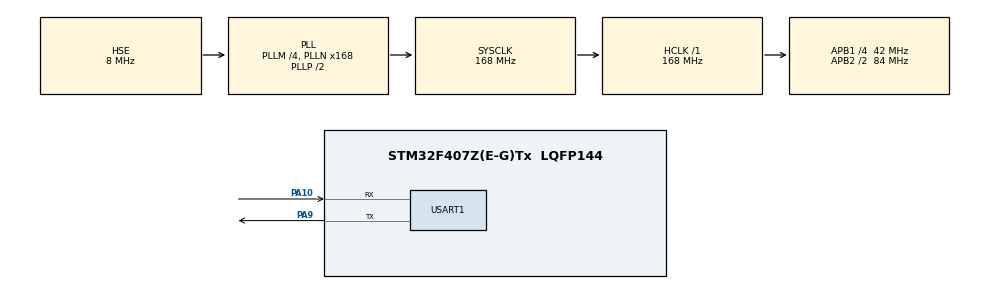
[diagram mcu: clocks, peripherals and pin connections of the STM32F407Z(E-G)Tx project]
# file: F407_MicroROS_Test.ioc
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Dma.Request0=USART1_RX
Dma.Request1=USART1_TX
Dma.USART1_RX.0.Direction=DMA_PERIPH_TO_MEMORY
Dma.USART1_RX.0.FIFOMode=DMA_FIFOMODE_DISABLE
Dma.USART1_RX.0.Instance=DMA2_Stream2
Dma.USART1_RX.0.MemDataAlignment=DMA_MDATAALIGN_BYTE
Dma.USART1_RX.0.MemInc=DMA_MINC_ENABLE
Dma.USART1_RX.0.Mode=DMA_CIRCULAR
Dma.USART1_RX.0.PeriphDataAlignment=DMA_PDATAALIGN_BYTE
Dma.USART1_RX.0.PeriphInc=DMA_PINC_DISABLE
Dma.USART1_RX.0.Priority=DMA_PRIORITY_VERY_HIGH
Dma.USART1_TX.1.Direction=DMA_MEMORY_TO_PERIPH
Dma.USART1_TX.1.FIFOMode=DMA_FIFOMODE_DISABLE
Dma.USART1_TX.1.Instance=DMA2_Stream7
Dma.USART1_TX.1.MemDataAlignment=DMA_MDATAALIGN_BYTE
Dma.USART1_TX.1.MemInc=DMA_MINC_ENABLE
Dma.USART1_TX.1.Mode=DMA_NORMAL
Dma.USART1_TX.1.PeriphDataAlignment=DMA_PDATAALIGN_BYTE
Dma.USART1_TX.1.PeriphInc=DMA_PINC_DISABLE
Dma.USART1_TX.1.Priority=DMA_PRIORITY_VERY_HIGH
FREERTOS.Tasks01=defaultTask,24,3000,StartDefaultTask,Default,NULL,Static,defaultTaskBuffer,defaultTaskControlBlock
Mcu.Family=STM32F4
Mcu.Name=STM32F407Z(E-G)Tx
Mcu.Package=LQFP144
NVIC.DMA2_Stream2_IRQn=true\:5\:0\:false\:false\:true\:true\:false\:true\:true
NVIC.DMA2_Stream7_IRQn=true\:5\:0\:false\:false\:true\:true\:false\:true\:true
NVIC.PriorityGroup=NVIC_PRIORITYGROUP_4
NVIC.TIM1_UP_TIM10_IRQn=true\:15\:0\:false\:false\:true\:false\:false\:true\:true
NVIC.TimeBase=TIM1_UP_TIM10_IRQn
NVIC.TimeBaseIP=TIM1
NVIC.USART1_IRQn=true\:5\:0\:false\:false\:true\:true\:false\:true\:true
PA10.Mode=Asynchronous
PA10.Signal=USART1_RX
PA13.Mode=Serial_Wire
PA13.Signal=SYS_JTMS-SWDIO
PA14.Mode=Serial_Wire
PA14.Signal=SYS_JTCK-SWCLK
PA9.Mode=Asynchronous
PA9.Signal=USART1_TX
PH0-OSC_IN.Mode=HSE-External-Oscillator
PH0-OSC_IN.Signal=RCC_OSC_IN
PH1-OSC_OUT.Mode=HSE-External-Oscillator
PH1-OSC_OUT.Signal=RCC_OSC_OUT
ProjectManager.HeapSize=0x200
ProjectManager.StackSize=0x400
ProjectManager.TargetToolchain=STM32CubeIDE
RCC.48MHZClocksFreq_Value=84000000
RCC.AHBFreq_Value=168000000
RCC.APB1CLKDivider=RCC_HCLK_DIV4
RCC.APB1Freq_Value=42000000
RCC.APB1TimFreq_Value=84000000
RCC.APB2CLKDivider=RCC_HCLK_DIV2
RCC.APB2Freq_Value=84000000
RCC.APB2TimFreq_Value=168000000
RCC.CortexFreq_Value=168000000
RCC.HCLKFreq_Value=168000000
RCC.HSE_VALUE=8000000
RCC.HSI_VALUE=16000000
RCC.LSE_VALUE=32768
RCC.PLLM=4
RCC.PLLN=168
RCC.PLLSourceVirtual=RCC_PLLSOURCE_HSE
RCC.SYSCLKFreq_VALUE=168000000
RCC.SYSCLKSource=RCC_SYSCLKSOURCE_PLLCLK
RCC.VCOOutputFreq_Value=336000000
USART1.VirtualMode=VM_ASYNC
VP_FREERTOS_VS_CMSIS_V2.Mode=CMSIS_V2
VP_SYS_VS_tim1.Mode=TIM1
board=custom

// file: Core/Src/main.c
/* USER CODE BEGIN Header */
/**
  ******************************************************************************
  * @file           : main.c
  * @brief          : Main program body
  ******************************************************************************
  * @attention
  *
  * Copyright (c) 2026 STMicroelectronics.
  * All rights reserved.
  *
  * This software is licensed under terms that can be found in the LICENSE file
  * in the root directory of this software component.
  * If no LICENSE file comes with this software, it is provided AS-IS.
  *
  ******************************************************************************
  */
/* USER CODE END Header */
#include "main.h"
#include "cmsis_os.h"
#include "dma.h"
#include "usart.h"
#include "gpio.h"

void SystemClock_Config(void);
void MX_FREERTOS_Init(void);

int main(void)
{

  /* MCU Configuration--------------------------------------------------------*/

  /* Reset of all peripherals, Initializes the Flash interface and the Systick. */
  HAL_Init();

  /* Configure the system clock */
  SystemClock_Config();

  /* Initialize all configured peripherals */
  MX_GPIO_Init();
  MX_DMA_Init();
  MX_USART1_UART_Init();

  /* Init scheduler */
  osKernelInitialize();  /* Call init function for freertos objects (in cmsis_os2.c) */
  MX_FREERTOS_Init();

  /* Start scheduler */
  osKernelStart();

  /* We should never get here as control is now taken by the scheduler */

  /* Infinite loop */
  while (1)
  {

  }
}

void SystemClock_Config(void)
{
  RCC_OscInitTypeDef RCC_OscInitStruct = {0};
  RCC_ClkInitTypeDef RCC_ClkInitStruct = {0};

  /** Configure the main internal regulator output voltage
  */
  __HAL_RCC_PWR_CLK_ENABLE();
  __HAL_PWR_VOLTAGESCALING_CONFIG(PWR_REGULATOR_VOLTAGE_SCALE1);

  /** Initializes the RCC Oscillators according to the specified parameters
  * in the RCC_OscInitTypeDef structure.
  */
  RCC_OscInitStruct.OscillatorType = RCC_OSCILLATORTYPE_HSE;
  RCC_OscInitStruct.HSEState = RCC_HSE_ON;
  RCC_OscInitStruct.PLL.PLLState = RCC_PLL_ON;
  RCC_OscInitStruct.PLL.PLLSource = RCC_PLLSOURCE_HSE;
  RCC_OscInitStruct.PLL.PLLM = 4;
  RCC_OscInitStruct.PLL.PLLN = 168;
  RCC_OscInitStruct.PLL.PLLP = RCC_PLLP_DIV2;
  RCC_OscInitStruct.PLL.PLLQ = 4;
  if (HAL_RCC_OscConfig(&RCC_OscInitStruct) != HAL_OK)
  {
    Error_Handler();
  }

  /** Initializes the CPU, AHB and APB buses clocks
  */
  RCC_ClkInitStruct.ClockType = RCC_CLOCKTYPE_HCLK|RCC_CLOCKTYPE_SYSCLK
                              |RCC_CLOCKTYPE_PCLK1|RCC_CLOCKTYPE_PCLK2;
  RCC_ClkInitStruct.SYSCLKSource = RCC_SYSCLKSOURCE_PLLCLK;
  RCC_ClkInitStruct.AHBCLKDivider = RCC_SYSCLK_DIV1;
  RCC_ClkInitStruct.APB1CLKDivider = RCC_HCLK_DIV4;
  RCC_ClkInitStruct.APB2CLKDivider = RCC_HCLK_DIV2;

  if (HAL_RCC_ClockConfig(&RCC_ClkInitStruct, FLASH_LATENCY_5) != HAL_OK)
  {
    Error_Handler();
  }
}

void HAL_TIM_PeriodElapsedCallback(TIM_HandleTypeDef *htim)
{
  if (htim->Instance == TIM1)
  {
    HAL_IncTick();
  }
}

void Error_Handler(void)
{
  __disable_irq();
  while (1)
  {
  }
}

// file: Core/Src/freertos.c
/* USER CODE BEGIN Header */
/**
  ******************************************************************************
  * File Name          : freertos.c
  * Description        : Code for freertos applications
  ******************************************************************************
  * @attention
  *
  * Copyright (c) 2026 STMicroelectronics.
  * All rights reserved.
  *
  * This software is licensed under terms that can be found in the LICENSE file
  * in the root directory of this software component.
  * If no LICENSE file comes with this software, it is provided AS-IS.
  *
  ******************************************************************************
  */
/* USER CODE END Header */

#include "FreeRTOS.h"
#include "task.h"
#include "main.h"
#include "cmsis_os.h"

/* USER CODE BEGIN Includes */
#include <stdbool.h>
#include <stddef.h>
#include <stdint.h>
#include <string.h>

#include <builtin_interfaces/msg/time.h>
#include <geometry_msgs/msg/transform_stamped.h>
#include <nav_msgs/msg/odometry.h>
#include <rcl/rcl.h>
#include <rcl/error_handling.h>
#include <rclc/rclc.h>
#include <rclc/executor.h>
#include <rcutils/allocator.h>
#include <rmw_microros/rmw_microros.h>
#include <rosidl_runtime_c/string_functions.h>
#include <std_msgs/msg/int32.h>
#include <tf2_msgs/msg/tf_message.h>
#include <uxr/client/transport.h>

#include "usart.h"
/* USER CODE END Includes */

typedef StaticTask_t osStaticThreadDef_t;

/* USER CODE BEGIN PD */
#define ODOM_FRAME_ID                 "odom"
#define BASE_FOOTPRINT_FRAME_ID       "base_footprint"
#define ODOM_TIMER_PERIOD_MS          50U
#define ODOM_LINEAR_X_MPS             0.1
#define PING_TIMER_PERIOD_MS          1000U
#define RCL_RETRY_DELAY_MS            500U
#define APP_ERROR_DELAY_MS            1000U
#define EXECUTOR_SPIN_TIMEOUT_MS      10U
#define EXECUTOR_LOOP_DELAY_MS        10U
#define APP_MILLISECONDS_PER_SECOND   1000.0
#define APP_NANOSECONDS_PER_SECOND    1000000000LL

/* USER CODE END PD */

/* USER CODE BEGIN PM */
#define RCL_RETRY_UNTIL_OK(call)          \
  do                                      \
  {                                       \
    while ((call) != RCL_RET_OK)          \
    {                                     \
      retry_after_rcl_error();            \
    }                                     \
  } while (0)

/* USER CODE END PM */

/* USER CODE BEGIN Variables */
static rcl_publisher_t odom_publisher;
static rcl_publisher_t tf_publisher;
static rcl_timer_t odom_timer;
static nav_msgs__msg__Odometry odom_msg;
static tf2_msgs__msg__TFMessage tf_msg;
static double simulated_x_m = 0.0;
static uint32_t odom_last_tick = 0U;

/* USER CODE END Variables */
/* Definitions for defaultTask */
osThreadId_t defaultTaskHandle;
uint32_t defaultTaskBuffer[ 3000 ];
osStaticThreadDef_t defaultTaskControlBlock;
const osThreadAttr_t defaultTask_attributes = {
  .name = "defaultTask",
  .cb_mem = &defaultTaskControlBlock,
  .cb_size = sizeof(defaultTaskControlBlock),
  .stack_mem = &defaultTaskBuffer[0],
  .stack_size = sizeof(defaultTaskBuffer),
  .priority = (osPriority_t) osPriorityNormal,
};

/* USER CODE BEGIN FunctionPrototypes */
bool cubemx_transport_open(struct uxrCustomTransport * transport);
bool cubemx_transport_close(struct uxrCustomTransport * transport);

size_t cubemx_transport_write(
    struct uxrCustomTransport * transport,
    const uint8_t * buf,
    size_t len,
    uint8_t * err);

size_t cubemx_transport_read(
    struct uxrCustomTransport * transport,
    uint8_t * buf,
    size_t len,
    int timeout,
    uint8_t * err);

void * microros_allocate(size_t size, void * state);
void microros_deallocate(void * pointer, void * state);
void * microros_reallocate(void * pointer, size_t size, void * state);
void * microros_zero_allocate(size_t number_of_elements, size_t size_of_element, void * state);

static bool init_odom_tf_messages(void);
static builtin_interfaces__msg__Time get_micro_ros_time(void);
static void odom_timer_callback(rcl_timer_t * timer, int64_t last_call_time);
static void stop_task_forever(void);
static void retry_after_rcl_error(void);
static bool publish_message(rcl_publisher_t * publisher, const void * message);

/* USER CODE END FunctionPrototypes */

void StartDefaultTask(void *argument);

void MX_FREERTOS_Init(void); /* (MISRA C 2004 rule 8.1) */

void MX_FREERTOS_Init(void) {

  /* Create the thread(s) */
  /* creation of defaultTask */
  defaultTaskHandle = osThreadNew(StartDefaultTask, NULL, &defaultTask_attributes);

}

void StartDefaultTask(void *argument)
{
  /* USER CODE BEGIN StartDefaultTask */

  (void) argument;

  rmw_uros_set_custom_transport(
      true,
      (void *) &huart1,
      cubemx_transport_open,
      cubemx_transport_close,
      cubemx_transport_write,
      cubemx_transport_read);

  rcl_allocator_t freeRTOS_allocator = rcutils_get_zero_initialized_allocator();

  freeRTOS_allocator.allocate = microros_allocate;
  freeRTOS_allocator.deallocate = microros_deallocate;
  freeRTOS_allocator.reallocate = microros_reallocate;
  freeRTOS_allocator.zero_allocate = microros_zero_allocate;

  if (!rcutils_set_default_allocator(&freeRTOS_allocator))
  {
    stop_task_forever();
  }

  rcl_allocator_t allocator = rcl_get_default_allocator();

  static rclc_support_t support;
  static rcl_node_t node;
  static rcl_publisher_t publisher;
  static rclc_executor_t executor;
  static std_msgs__msg__Int32 msg;

  RCL_RETRY_UNTIL_OK(rclc_support_init(&support, 0, NULL, &allocator));
  RCL_RETRY_UNTIL_OK(rclc_node_init_default(&node, "stm32_f407_node", "", &support));

  RCL_RETRY_UNTIL_OK(rclc_publisher_init_default(
      &publisher,
      &node,
      ROSIDL_GET_MSG_TYPE_SUPPORT(std_msgs, msg, Int32),
      "/stm32_ping"));

  RCL_RETRY_UNTIL_OK(rclc_publisher_init_default(
      &odom_publisher,
      &node,
      ROSIDL_GET_MSG_TYPE_SUPPORT(nav_msgs, msg, Odometry),
      "/odom"));

  RCL_RETRY_UNTIL_OK(rclc_publisher_init_default(
      &tf_publisher,
      &node,
      ROSIDL_GET_MSG_TYPE_SUPPORT(tf2_msgs, msg, TFMessage),
      "/tf"));

  if (!init_odom_tf_messages())
  {
    stop_task_forever();
  }

  (void) rmw_uros_sync_session(1000);

  RCL_RETRY_UNTIL_OK(rclc_timer_init_default(
      &odom_timer,
      &support,
      RCL_MS_TO_NS(ODOM_TIMER_PERIOD_MS),
      odom_timer_callback));

  RCL_RETRY_UNTIL_OK(rclc_executor_init(&executor, &support.context, 1, &allocator));

  msg.data = 0;

  RCL_RETRY_UNTIL_OK(rclc_executor_add_timer(&executor, &odom_timer));

  uint32_t last_publish = osKernelGetTickCount();

  for (;;)
  {
    uint32_t now = osKernelGetTickCount();

    if ((now - last_publish) >= pdMS_TO_TICKS(PING_TIMER_PERIOD_MS))
    {
      last_publish = now;

      if (publish_message(&publisher, &msg))
      {
        msg.data++;
      }
    }

    rcl_ret_t spin_ret = rclc_executor_spin_some(&executor, RCL_MS_TO_NS(EXECUTOR_SPIN_TIMEOUT_MS));

    if ((spin_ret != RCL_RET_OK) && (spin_ret != RCL_RET_TIMEOUT))
    {
      rcl_reset_error();
    }

    osDelay(EXECUTOR_LOOP_DELAY_MS);
  }

  /* USER CODE END StartDefaultTask */
}

/* USER CODE BEGIN Application */

static bool init_odom_tf_messages(void)
{
  memset(&odom_msg, 0, sizeof(odom_msg));
  memset(&tf_msg, 0, sizeof(tf_msg));

  if (!nav_msgs__msg__Odometry__init(&odom_msg))
  {
    return false;
  }

  if (!geometry_msgs__msg__TransformStamped__Sequence__init(&tf_msg.transforms, 1))
  {
    nav_msgs__msg__Odometry__fini(&odom_msg);
    return false;
  }

  geometry_msgs__msg__TransformStamped * tf = &tf_msg.transforms.data[0];

  if (!rosidl_runtime_c__String__assign(&odom_msg.header.frame_id, ODOM_FRAME_ID) ||
      !rosidl_runtime_c__String__assign(&odom_msg.child_frame_id, BASE_FOOTPRINT_FRAME_ID) ||
      !rosidl_runtime_c__String__assign(&tf->header.frame_id, ODOM_FRAME_ID) ||
      !rosidl_runtime_c__String__assign(&tf->child_frame_id, BASE_FOOTPRINT_FRAME_ID))
  {
    geometry_msgs__msg__TransformStamped__Sequence__fini(&tf_msg.transforms);
    nav_msgs__msg__Odometry__fini(&odom_msg);
    return false;
  }

  odom_msg.pose.pose.orientation.w = 1.0;
  odom_msg.twist.twist.linear.x = ODOM_LINEAR_X_MPS;
  odom_msg.twist.twist.linear.y = 0.0;
  odom_msg.twist.twist.linear.z = 0.0;
  odom_msg.twist.twist.angular.x = 0.0;
  odom_msg.twist.twist.angular.y = 0.0;
  odom_msg.twist.twist.angular.z = 0.0;

  tf->transform.translation.y = 0.0;
  tf->transform.translation.z = 0.0;
  tf->transform.rotation.x = 0.0;
  tf->transform.rotation.y = 0.0;
  tf->transform.rotation.z = 0.0;
  tf->transform.rotation.w = 1.0;

  simulated_x_m = 0.0;
  odom_last_tick = 0U;

  return true;
}

static builtin_interfaces__msg__Time get_micro_ros_time(void)
{
  builtin_interfaces__msg__Time stamp = {0};
  int64_t now_ns = 0;

  if (rmw_uros_epoch_synchronized())
  {
    now_ns = rmw_uros_epoch_nanos();
  }
  else
  {
    now_ns = ((int64_t) osKernelGetTickCount() * APP_NANOSECONDS_PER_SECOND) / configTICK_RATE_HZ;
  }

  if (now_ns < 0)
  {
    now_ns = 0;
  }

  stamp.sec = (int32_t) (now_ns / APP_NANOSECONDS_PER_SECOND);
  stamp.nanosec = (uint32_t) (now_ns % APP_NANOSECONDS_PER_SECOND);

  return stamp;
}

static void odom_timer_callback(rcl_timer_t * timer, int64_t last_call_time)
{
  (void) last_call_time;

  if (timer == NULL)
  {
    return;
  }

  uint32_t now_tick = osKernelGetTickCount();
  double dt = (double) ODOM_TIMER_PERIOD_MS / APP_MILLISECONDS_PER_SECOND;

  if (odom_last_tick != 0U)
  {
    dt = (double) (now_tick - odom_last_tick) / (double) configTICK_RATE_HZ;
  }

  odom_last_tick = now_tick;
  simulated_x_m += ODOM_LINEAR_X_MPS * dt;

  builtin_interfaces__msg__Time stamp = get_micro_ros_time();

  odom_msg.header.stamp = stamp;
  odom_msg.pose.pose.position.x = simulated_x_m;

  geometry_msgs__msg__TransformStamped * tf = &tf_msg.transforms.data[0];
  tf->header.stamp = stamp;
  tf->transform.translation.x = simulated_x_m;

  (void) publish_message(&odom_publisher, &odom_msg);
  (void) publish_message(&tf_publisher, &tf_msg);
}

static void stop_task_forever(void)
{
  for (;;)
  {
    osDelay(APP_ERROR_DELAY_MS);
  }
}

static void retry_after_rcl_error(void)
{
  rcl_reset_error();
  osDelay(RCL_RETRY_DELAY_MS);
}

static bool publish_message(rcl_publisher_t * publisher, const void * message)
{
  if (rcl_publish(publisher, message, NULL) == RCL_RET_OK)
  {
    return true;
  }

  rcl_reset_error();
  return false;
}

/* USER CODE END Application */
